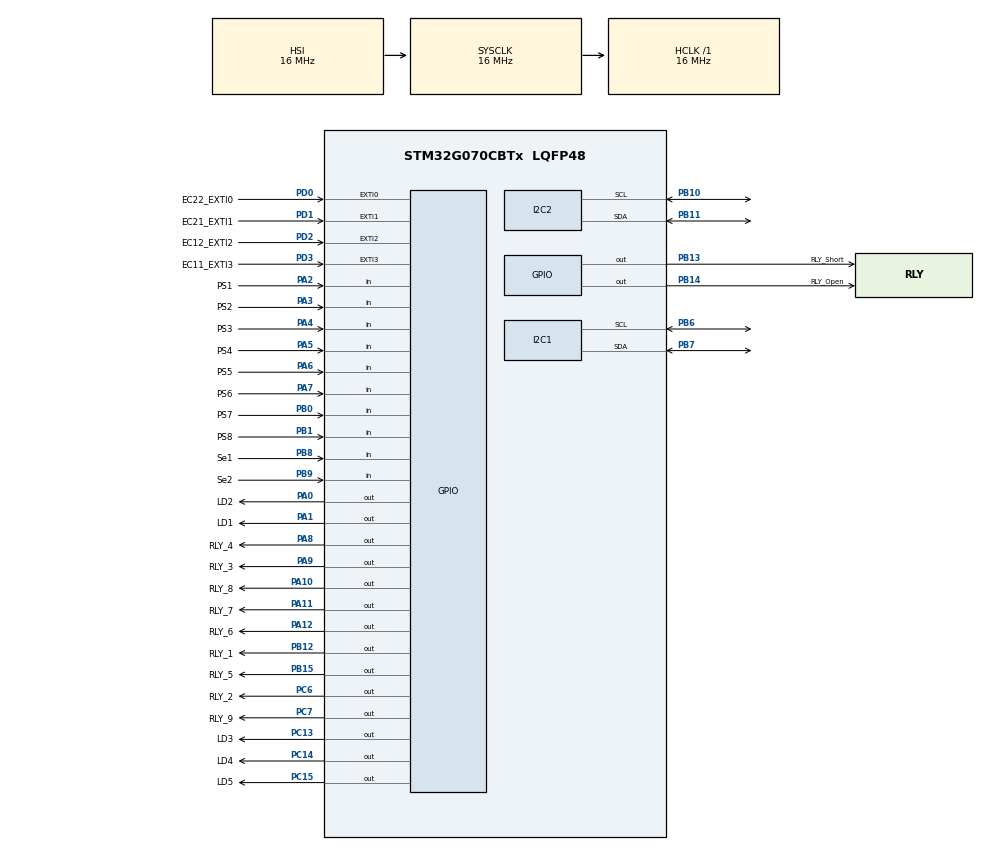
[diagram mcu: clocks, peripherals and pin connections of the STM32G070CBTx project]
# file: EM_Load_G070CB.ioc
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Dma.I2C2_RX.0.Direction=DMA_PERIPH_TO_MEMORY
Dma.I2C2_RX.0.EventEnable=DISABLE
Dma.I2C2_RX.0.Instance=DMA1_Channel1
Dma.I2C2_RX.0.MemDataAlignment=DMA_MDATAALIGN_BYTE
Dma.I2C2_RX.0.MemInc=DMA_MINC_ENABLE
Dma.I2C2_RX.0.Mode=DMA_NORMAL
Dma.I2C2_RX.0.PeriphDataAlignment=DMA_PDATAALIGN_BYTE
Dma.I2C2_RX.0.PeriphInc=DMA_PINC_DISABLE
Dma.I2C2_RX.0.Polarity=HAL_DMAMUX_REQ_GEN_RISING
Dma.I2C2_RX.0.Priority=DMA_PRIORITY_LOW
Dma.I2C2_RX.0.RequestNumber=1
Dma.I2C2_RX.0.SignalID=NONE
Dma.I2C2_RX.0.SyncEnable=DISABLE
Dma.I2C2_RX.0.SyncPolarity=HAL_DMAMUX_SYNC_NO_EVENT
Dma.I2C2_RX.0.SyncRequestNumber=1
Dma.I2C2_RX.0.SyncSignalID=NONE
Dma.I2C2_TX.1.Direction=DMA_MEMORY_TO_PERIPH
Dma.I2C2_TX.1.EventEnable=DISABLE
Dma.I2C2_TX.1.Instance=DMA1_Channel2
Dma.I2C2_TX.1.MemDataAlignment=DMA_MDATAALIGN_BYTE
Dma.I2C2_TX.1.MemInc=DMA_MINC_ENABLE
Dma.I2C2_TX.1.Mode=DMA_NORMAL
Dma.I2C2_TX.1.PeriphDataAlignment=DMA_PDATAALIGN_BYTE
Dma.I2C2_TX.1.PeriphInc=DMA_PINC_DISABLE
Dma.I2C2_TX.1.Polarity=HAL_DMAMUX_REQ_GEN_RISING
Dma.I2C2_TX.1.Priority=DMA_PRIORITY_LOW
Dma.I2C2_TX.1.RequestNumber=1
Dma.I2C2_TX.1.SignalID=NONE
Dma.I2C2_TX.1.SyncEnable=DISABLE
Dma.I2C2_TX.1.SyncPolarity=HAL_DMAMUX_SYNC_NO_EVENT
Dma.I2C2_TX.1.SyncRequestNumber=1
Dma.I2C2_TX.1.SyncSignalID=NONE
Dma.Request0=I2C2_RX
Dma.Request1=I2C2_TX
I2C2.OwnAddress=0x7A
Mcu.Family=STM32G0
Mcu.Name=STM32G070CBTx
Mcu.Package=LQFP48
NVIC.DMA1_Channel1_IRQn=true\:0\:0\:false\:false\:true\:false\:true\:true
NVIC.DMA1_Channel2_3_IRQn=true\:0\:0\:false\:false\:true\:false\:true\:true
NVIC.EXTI0_1_IRQn=true\:1\:0\:true\:false\:true\:true\:true\:true
NVIC.EXTI2_3_IRQn=true\:1\:0\:true\:false\:true\:true\:true\:true
NVIC.I2C2_IRQn=true\:0\:0\:false\:false\:true\:true\:true\:true
PA0.GPIO_Label=LD2
PA0.Signal=GPIO_Output
PA1.GPIO_Label=LD1
PA1.Signal=GPIO_Output
PA10.GPIO_Label=RLY_8
PA10.Signal=GPIO_Output
PA11\ [PA9].GPIO_Label=RLY_7
PA11\ [PA9].Signal=GPIO_Output
PA12\ [PA10].GPIO_Label=RLY_6
PA12\ [PA10].Signal=GPIO_Output
PA13.Mode=Serial_Wire
PA13.Signal=SYS_SWDIO
PA14-BOOT0.Mode=Serial_Wire
PA14-BOOT0.Signal=SYS_SWCLK
PA2.GPIO_Label=PS1
PA2.GPIO_PuPd=GPIO_PULLUP
PA2.Signal=GPIO_Input
PA3.GPIO_Label=PS2
PA3.GPIO_PuPd=GPIO_PULLUP
PA3.Signal=GPIO_Input
PA4.GPIO_Label=PS3
PA4.GPIO_PuPd=GPIO_PULLUP
PA4.Signal=GPIO_Input
PA5.GPIO_Label=PS4
PA5.GPIO_PuPd=GPIO_PULLUP
PA5.Signal=GPIO_Input
PA6.GPIO_Label=PS5
PA6.GPIO_PuPd=GPIO_PULLUP
PA6.Signal=GPIO_Input
PA7.GPIO_Label=PS6
PA7.GPIO_PuPd=GPIO_PULLUP
PA7.Signal=GPIO_Input
PA8.GPIO_Label=RLY_4
PA8.Signal=GPIO_Output
PA9.GPIO_Label=RLY_3
PA9.Signal=GPIO_Output
PB0.GPIO_Label=PS7
PB0.GPIO_PuPd=GPIO_PULLUP
PB0.Signal=GPIO_Input
PB1.GPIO_Label=PS8
PB1.GPIO_PuPd=GPIO_PULLUP
PB1.Signal=GPIO_Input
PB10.Mode=I2C
PB10.Signal=I2C2_SCL
PB11.Mode=I2C
PB11.Signal=I2C2_SDA
PB12.GPIO_Label=RLY_1
PB12.Signal=GPIO_Output
PB13.GPIO_Label=RLY_Short
PB13.Signal=GPIO_Output
PB14.GPIO_Label=RLY_Open
PB14.Signal=GPIO_Output
PB15.GPIO_Label=RLY_5
PB15.Signal=GPIO_Output
PB6.Mode=I2C
PB6.Signal=I2C1_SCL
PB7.Mode=I2C
PB7.Signal=I2C1_SDA
PB8.GPIO_Label=Se1
PB8.GPIO_PuPd=GPIO_PULLUP
PB8.Signal=GPIO_Input
PB9.GPIO_Label=Se2
PB9.GPIO_PuPd=GPIO_PULLUP
PB9.Signal=GPIO_Input
PC13.GPIO_Label=LD3
PC13.Signal=GPIO_Output
PC14-OSC32_IN\ (PC14).GPIO_Label=LD4
PC14-OSC32_IN\ (PC14).Signal=GPIO_Output
PC15-OSC32_OUT\ (PC15).GPIO_Label=LD5
PC15-OSC32_OUT\ (PC15).Signal=GPIO_Output
PC6.GPIO_Label=RLY_2
PC6.Signal=GPIO_Output
PC7.GPIO_Label=RLY_9
PC7.Signal=GPIO_Output
PD0.GPIO_Label=EC22_EXTI0
PD0.GPIO_ModeDefaultEXTI=GPIO_MODE_IT_RISING_FALLING
PD0.Signal=GPXTI0
PD1.GPIO_Label=EC21_EXTI1
PD1.GPIO_ModeDefaultEXTI=GPIO_MODE_IT_RISING_FALLING
PD1.Signal=GPXTI1
PD2.GPIO_Label=EC12_EXTI2
PD2.GPIO_ModeDefaultEXTI=GPIO_MODE_IT_RISING_FALLING
PD2.Signal=GPXTI2
PD3.GPIO_Label=EC11_EXTI3
PD3.GPIO_ModeDefaultEXTI=GPIO_MODE_IT_RISING_FALLING
PD3.Signal=GPXTI3
ProjectManager.HeapSize=0x200
ProjectManager.StackSize=0x400
ProjectManager.TargetToolchain=STM32CubeIDE
RCC.AHBFreq_Value=16000000
RCC.CortexFreq_Value=16000000
RCC.EXTERNAL_CLOCK_VALUE=48000
RCC.HCLKFreq_Value=16000000
RCC.HSE_VALUE=8000000
RCC.HSI_VALUE=16000000
RCC.LSE_VALUE=32768
RCC.SYSCLKFreq_VALUE=16000000
RCC.VCOOutputFreq_Value=128000000
VP_CRC_VS_CRC.Mode=CRC_Activate
VP_SYS_VS_DBSignals.Mode=DisableDeadBatterySignals
board=custom

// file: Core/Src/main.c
/* USER CODE BEGIN Header */
/**
  ******************************************************************************
  * @file           : main.c
  * @brief          : Main program body
  ******************************************************************************
  * @attention
  *
  * Copyright (c) 2024 STMicroelectronics.
  * All rights reserved.
  *
  * This software is licensed under terms that can be found in the LICENSE file
  * in the root directory of this software component.
  * If no LICENSE file comes with this software, it is provided AS-IS.
  *
  ******************************************************************************
  */
/* USER CODE END Header */
#include "main.h"

/* USER CODE BEGIN Includes */
#include "App.h"
#include "Generic/Generic.h"
/* USER CODE END Includes */

I2C_HandleTypeDef hi2c1;

void SystemClock_Config(void);
static void MX_GPIO_Init(void);
static void MX_I2C1_Init(void);
static void MX_DMA_Init(void);
static void MX_I2C2_Init(void);
static void MX_CRC_Init(void);

int main(void)
{

  /* MCU Configuration--------------------------------------------------------*/

  /* Reset of all peripherals, Initializes the Flash interface and the Systick. */
  HAL_Init();

  /* Configure the system clock */
  SystemClock_Config();

  /* Initialize all configured peripherals */
  MX_GPIO_Init();
  MX_I2C1_Init();
  MX_DMA_Init();
  MX_I2C2_Init();
  MX_CRC_Init();
  /* USER CODE BEGIN 2 */
  AppInit();
  /* USER CODE END 2 */

  /* Infinite loop */
  /* USER CODE BEGIN WHILE */
  while (1)
  {
	AppTask();
    /* USER CODE END WHILE */

  }
}

void SystemClock_Config(void)
{
  RCC_OscInitTypeDef RCC_OscInitStruct = {0};
  RCC_ClkInitTypeDef RCC_ClkInitStruct = {0};

  /** Configure the main internal regulator output voltage
  */
  HAL_PWREx_ControlVoltageScaling(PWR_REGULATOR_VOLTAGE_SCALE1);

  /** Initializes the RCC Oscillators according to the specified parameters
  * in the RCC_OscInitTypeDef structure.
  */
  RCC_OscInitStruct.OscillatorType = RCC_OSCILLATORTYPE_HSI;
  RCC_OscInitStruct.HSIState = RCC_HSI_ON;
  RCC_OscInitStruct.HSIDiv = RCC_HSI_DIV1;
  RCC_OscInitStruct.HSICalibrationValue = RCC_HSICALIBRATION_DEFAULT;
  RCC_OscInitStruct.PLL.PLLState = RCC_PLL_NONE;
  if (HAL_RCC_OscConfig(&RCC_OscInitStruct) != HAL_OK)
  {
    Error_Handler();
  }

  /** Initializes the CPU, AHB and APB buses clocks
  */
  RCC_ClkInitStruct.ClockType = RCC_CLOCKTYPE_HCLK|RCC_CLOCKTYPE_SYSCLK
                              |RCC_CLOCKTYPE_PCLK1;
  RCC_ClkInitStruct.SYSCLKSource = RCC_SYSCLKSOURCE_HSI;
  RCC_ClkInitStruct.AHBCLKDivider = RCC_SYSCLK_DIV1;
  RCC_ClkInitStruct.APB1CLKDivider = RCC_HCLK_DIV1;

  if (HAL_RCC_ClockConfig(&RCC_ClkInitStruct, FLASH_LATENCY_0) != HAL_OK)
  {
    Error_Handler();
  }
}

static void MX_CRC_Init(void)
{

  /* Peripheral clock enable */
  LL_AHB1_GRP1_EnableClock(LL_AHB1_GRP1_PERIPH_CRC);

  LL_CRC_SetInputDataReverseMode(CRC, LL_CRC_INDATA_REVERSE_NONE);
  LL_CRC_SetOutputDataReverseMode(CRC, LL_CRC_OUTDATA_REVERSE_NONE);
  LL_CRC_SetPolynomialCoef(CRC, LL_CRC_DEFAULT_CRC32_POLY);
  LL_CRC_SetPolynomialSize(CRC, LL_CRC_POLYLENGTH_32B);
  LL_CRC_SetInitialData(CRC, LL_CRC_DEFAULT_CRC_INITVALUE);

}

static void MX_I2C1_Init(void)
{

  hi2c1.Instance = I2C1;
  hi2c1.Init.Timing = 0x00303D5B;
  hi2c1.Init.OwnAddress1 = 0;
  hi2c1.Init.AddressingMode = I2C_ADDRESSINGMODE_7BIT;
  hi2c1.Init.DualAddressMode = I2C_DUALADDRESS_DISABLE;
  hi2c1.Init.OwnAddress2 = 0;
  hi2c1.Init.OwnAddress2Masks = I2C_OA2_NOMASK;
  hi2c1.Init.GeneralCallMode = I2C_GENERALCALL_DISABLE;
  hi2c1.Init.NoStretchMode = I2C_NOSTRETCH_DISABLE;
  if (HAL_I2C_Init(&hi2c1) != HAL_OK)
  {
    Error_Handler();
  }

  /** Configure Analogue filter
  */
  if (HAL_I2CEx_ConfigAnalogFilter(&hi2c1, I2C_ANALOGFILTER_ENABLE) != HAL_OK)
  {
    Error_Handler();
  }

  /** Configure Digital filter
  */
  if (HAL_I2CEx_ConfigDigitalFilter(&hi2c1, 0) != HAL_OK)
  {
    Error_Handler();
  }

}

static void MX_I2C2_Init(void)
{

  LL_I2C_InitTypeDef I2C_InitStruct = {0};

  LL_GPIO_InitTypeDef GPIO_InitStruct = {0};

  LL_IOP_GRP1_EnableClock(LL_IOP_GRP1_PERIPH_GPIOB);
  /**I2C2 GPIO Configuration
  PB10   ------> I2C2_SCL
  PB11   ------> I2C2_SDA
  */
  GPIO_InitStruct.Pin = LL_GPIO_PIN_10;
  GPIO_InitStruct.Mode = LL_GPIO_MODE_ALTERNATE;
  GPIO_InitStruct.Speed = LL_GPIO_SPEED_FREQ_LOW;
  GPIO_InitStruct.OutputType = LL_GPIO_OUTPUT_OPENDRAIN;
  GPIO_InitStruct.Pull = LL_GPIO_PULL_NO;
  GPIO_InitStruct.Alternate = LL_GPIO_AF_6;
  LL_GPIO_Init(GPIOB, &GPIO_InitStruct);

  GPIO_InitStruct.Pin = LL_GPIO_PIN_11;
  GPIO_InitStruct.Mode = LL_GPIO_MODE_ALTERNATE;
  GPIO_InitStruct.Speed = LL_GPIO_SPEED_FREQ_LOW;
  GPIO_InitStruct.OutputType = LL_GPIO_OUTPUT_OPENDRAIN;
  GPIO_InitStruct.Pull = LL_GPIO_PULL_NO;
  GPIO_InitStruct.Alternate = LL_GPIO_AF_6;
  LL_GPIO_Init(GPIOB, &GPIO_InitStruct);

  /* Peripheral clock enable */
  LL_APB1_GRP1_EnableClock(LL_APB1_GRP1_PERIPH_I2C2);

  /* I2C2 DMA Init */

  /* I2C2_RX Init */
  LL_DMA_SetPeriphRequest(DMA1, LL_DMA_CHANNEL_1, LL_DMAMUX_REQ_I2C2_RX);

  LL_DMA_SetDataTransferDirection(DMA1, LL_DMA_CHANNEL_1, LL_DMA_DIRECTION_PERIPH_TO_MEMORY);

  LL_DMA_SetChannelPriorityLevel(DMA1, LL_DMA_CHANNEL_1, LL_DMA_PRIORITY_LOW);

  LL_DMA_SetMode(DMA1, LL_DMA_CHANNEL_1, LL_DMA_MODE_NORMAL);

  LL_DMA_SetPeriphIncMode(DMA1, LL_DMA_CHANNEL_1, LL_DMA_PERIPH_NOINCREMENT);

  LL_DMA_SetMemoryIncMode(DMA1, LL_DMA_CHANNEL_1, LL_DMA_MEMORY_INCREMENT);

  LL_DMA_SetPeriphSize(DMA1, LL_DMA_CHANNEL_1, LL_DMA_PDATAALIGN_BYTE);

  LL_DMA_SetMemorySize(DMA1, LL_DMA_CHANNEL_1, LL_DMA_MDATAALIGN_BYTE);

  /* I2C2_TX Init */
  LL_DMA_SetPeriphRequest(DMA1, LL_DMA_CHANNEL_2, LL_DMAMUX_REQ_I2C2_TX);

  LL_DMA_SetDataTransferDirection(DMA1, LL_DMA_CHANNEL_2, LL_DMA_DIRECTION_MEMORY_TO_PERIPH);

  LL_DMA_SetChannelPriorityLevel(DMA1, LL_DMA_CHANNEL_2, LL_DMA_PRIORITY_LOW);

  LL_DMA_SetMode(DMA1, LL_DMA_CHANNEL_2, LL_DMA_MODE_NORMAL);

  LL_DMA_SetPeriphIncMode(DMA1, LL_DMA_CHANNEL_2, LL_DMA_PERIPH_NOINCREMENT);

  LL_DMA_SetMemoryIncMode(DMA1, LL_DMA_CHANNEL_2, LL_DMA_MEMORY_INCREMENT);

  LL_DMA_SetPeriphSize(DMA1, LL_DMA_CHANNEL_2, LL_DMA_PDATAALIGN_BYTE);

  LL_DMA_SetMemorySize(DMA1, LL_DMA_CHANNEL_2, LL_DMA_MDATAALIGN_BYTE);

  /* I2C2 interrupt Init */
  NVIC_SetPriority(I2C2_IRQn, 0);
  NVIC_EnableIRQ(I2C2_IRQn);

  /** I2C Initialization
  */
  I2C_InitStruct.PeripheralMode = LL_I2C_MODE_I2C;
  I2C_InitStruct.Timing = 0x00303D5B;
  I2C_InitStruct.AnalogFilter = LL_I2C_ANALOGFILTER_ENABLE;
  I2C_InitStruct.DigitalFilter = 0;
  I2C_InitStruct.OwnAddress1 = 244;
  I2C_InitStruct.TypeAcknowledge = LL_I2C_ACK;
  I2C_InitStruct.OwnAddrSize = LL_I2C_OWNADDRESS1_7BIT;
  LL_I2C_Init(I2C2, &I2C_InitStruct);
  LL_I2C_EnableAutoEndMode(I2C2);
  LL_I2C_SetOwnAddress2(I2C2, 0, LL_I2C_OWNADDRESS2_NOMASK);
  LL_I2C_DisableOwnAddress2(I2C2);
  LL_I2C_DisableGeneralCall(I2C2);
  LL_I2C_EnableClockStretching(I2C2);

}

static void MX_DMA_Init(void)
{

  /* DMA controller clock enable */
  __HAL_RCC_DMA1_CLK_ENABLE();

  /* DMA interrupt init */
  /* DMA1_Channel1_IRQn interrupt configuration */
  NVIC_SetPriority(DMA1_Channel1_IRQn, 0);
  NVIC_EnableIRQ(DMA1_Channel1_IRQn);
  /* DMA1_Channel2_3_IRQn interrupt configuration */
  NVIC_SetPriority(DMA1_Channel2_3_IRQn, 0);
  NVIC_EnableIRQ(DMA1_Channel2_3_IRQn);

}

static void MX_GPIO_Init(void)
{
  GPIO_InitTypeDef GPIO_InitStruct = {0};

  /* GPIO Ports Clock Enable */
  __HAL_RCC_GPIOC_CLK_ENABLE();
  __HAL_RCC_GPIOA_CLK_ENABLE();
  __HAL_RCC_GPIOB_CLK_ENABLE();
  __HAL_RCC_GPIOD_CLK_ENABLE();

  /*Configure GPIO pin Output Level */
  HAL_GPIO_WritePin(GPIOC, LD3_Pin|LD4_Pin|LD5_Pin|RLY_2_Pin
                          |RLY_9_Pin, GPIO_PIN_RESET);

  /*Configure GPIO pin Output Level */
  HAL_GPIO_WritePin(GPIOA, LD2_Pin|LD1_Pin|RLY_4_Pin|RLY_3_Pin
                          |RLY_8_Pin|RLY_7_Pin|RLY_6_Pin, GPIO_PIN_RESET);

  /*Configure GPIO pin Output Level */
  HAL_GPIO_WritePin(GPIOB, RLY_1_Pin|RLY_Short_Pin|RLY_Open_Pin|RLY_5_Pin, GPIO_PIN_RESET);

  /*Configure GPIO pins : LD3_Pin LD4_Pin LD5_Pin RLY_2_Pin
                           RLY_9_Pin */
  GPIO_InitStruct.Pin = LD3_Pin|LD4_Pin|LD5_Pin|RLY_2_Pin
                          |RLY_9_Pin;
  GPIO_InitStruct.Mode = GPIO_MODE_OUTPUT_PP;
  GPIO_InitStruct.Pull = GPIO_NOPULL;
  GPIO_InitStruct.Speed = GPIO_SPEED_FREQ_LOW;
  HAL_GPIO_Init(GPIOC, &GPIO_InitStruct);

  /*Configure GPIO pins : LD2_Pin LD1_Pin RLY_4_Pin RLY_3_Pin
                           RLY_8_Pin RLY_7_Pin RLY_6_Pin */
  GPIO_InitStruct.Pin = LD2_Pin|LD1_Pin|RLY_4_Pin|RLY_3_Pin
                          |RLY_8_Pin|RLY_7_Pin|RLY_6_Pin;
  GPIO_InitStruct.Mode = GPIO_MODE_OUTPUT_PP;
  GPIO_InitStruct.Pull = GPIO_NOPULL;
  GPIO_InitStruct.Speed = GPIO_SPEED_FREQ_LOW;
  HAL_GPIO_Init(GPIOA, &GPIO_InitStruct);

  /*Configure GPIO pins : PS1_Pin PS2_Pin PS3_Pin PS4_Pin
                           PS5_Pin PS6_Pin */
  GPIO_InitStruct.Pin = PS1_Pin|PS2_Pin|PS3_Pin|PS4_Pin
                          |PS5_Pin|PS6_Pin;
  GPIO_InitStruct.Mode = GPIO_MODE_INPUT;
  GPIO_InitStruct.Pull = GPIO_PULLUP;
  HAL_GPIO_Init(GPIOA, &GPIO_InitStruct);

  /*Configure GPIO pins : PS7_Pin PS8_Pin Se1_Pin Se2_Pin */
  GPIO_InitStruct.Pin = PS7_Pin|PS8_Pin|Se1_Pin|Se2_Pin;
  GPIO_InitStruct.Mode = GPIO_MODE_INPUT;
  GPIO_InitStruct.Pull = GPIO_PULLUP;
  HAL_GPIO_Init(GPIOB, &GPIO_InitStruct);

  /*Configure GPIO pins : RLY_1_Pin RLY_Short_Pin RLY_Open_Pin RLY_5_Pin */
  GPIO_InitStruct.Pin = RLY_1_Pin|RLY_Short_Pin|RLY_Open_Pin|RLY_5_Pin;
  GPIO_InitStruct.Mode = GPIO_MODE_OUTPUT_PP;
  GPIO_InitStruct.Pull = GPIO_NOPULL;
  GPIO_InitStruct.Speed = GPIO_SPEED_FREQ_LOW;
  HAL_GPIO_Init(GPIOB, &GPIO_InitStruct);

  /*Configure GPIO pins : EC22_EXTI0_Pin EC21_EXTI1_Pin EC12_EXTI2_Pin EC11_EXTI3_Pin */
  GPIO_InitStruct.Pin = EC22_EXTI0_Pin|EC21_EXTI1_Pin|EC12_EXTI2_Pin|EC11_EXTI3_Pin;
  GPIO_InitStruct.Mode = GPIO_MODE_IT_RISING_FALLING;
  GPIO_InitStruct.Pull = GPIO_NOPULL;
  HAL_GPIO_Init(GPIOD, &GPIO_InitStruct);

  /* EXTI interrupt init*/
  HAL_NVIC_SetPriority(EXTI0_1_IRQn, 1, 0);
  HAL_NVIC_EnableIRQ(EXTI0_1_IRQn);

  HAL_NVIC_SetPriority(EXTI2_3_IRQn, 1, 0);
  HAL_NVIC_EnableIRQ(EXTI2_3_IRQn);

}

void Error_Handler(void)
{
  /* USER CODE BEGIN Error_Handler_Debug */
  /* User can add his own implementation to report the HAL error return state */
  __disable_irq();

  //HAL_NVIC_SystemReset();

  //while (1)
  {
  }
  /* USER CODE END Error_Handler_Debug */
}
